VERSION ""

NS_ :

BS_:

BU_: BLE GEO IO MASTER MOTOR SENSOR

BO_ 010 BLE_COMM_CMD: 1 BLE
 SG_ BLE_COMM_CMD_enum : 0|8@1+ (1,0) [0|0] "" MASTER

BO_ 100 SYSTEM_CMD: 1 MASTER
 SG_ SYSTEM_CMD_enum : 0|8@1+ (1,0) [0|0] "" BLE,GEO,IO,MOTOR,SENSOR

BO_ 134 MASTER_HEARTBEAT: 4 MASTER
 SG_ MASTER_HEARTBEAT_rx_bytes : 0|16@1+ (1,0) [0|0] "" BLE
 SG_ MASTER_HEARTBEAT_tx_bytes : 16|16@1+ (1,0) [0|0] "" BLE

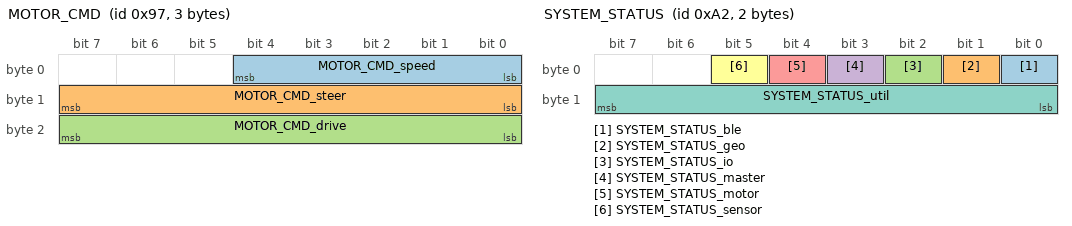
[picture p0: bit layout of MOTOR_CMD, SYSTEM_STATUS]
BO_ 151 MOTOR_CMD: 3 MASTER
 SG_ MOTOR_CMD_speed : 0|5@1+ (1,0) [10|20] "%" MOTOR,IO
 SG_ MOTOR_CMD_steer : 8|8@1+ (1,0) [0|0] "" MOTOR,IO
 SG_ MOTOR_CMD_drive : 16|8@1+ (1,0) [0|0] "" MOTOR,IO

BO_ 162 SYSTEM_STATUS: 2 MASTER
 SG_ SYSTEM_STATUS_ble : 0|1@1+ (1,0) [0|0] "" BLE,IO
 SG_ SYSTEM_STATUS_geo : 1|1@1+ (1,0) [0|0] "" BLE,IO
 SG_ SYSTEM_STATUS_io : 2|1@1+ (1,0) [0|0] "" BLE,IO
 SG_ SYSTEM_STATUS_master : 3|1@1+ (1,0) [0|0] "" BLE,IO
 SG_ SYSTEM_STATUS_motor : 4|1@1+ (1,0) [0|0] "" BLE,IO
 SG_ SYSTEM_STATUS_sensor : 5|1@1+ (1,0) [0|0] "" BLE,IO
 SG_ SYSTEM_STATUS_util : 8|8@1+ (1,0) [0|100] "%" BLE,IO

BO_ 211 SENSOR_ULTRASONIC: 7 SENSOR
 SG_ SENSOR_ULTRASONIC_mux M : 0|4@1+ (1,0) [0|0] "" MASTER
 SG_ SENSOR_ULTRASONIC_err_count : 4|12@1+ (1,0) [0|0] "" MASTER
 SG_ SENSOR_ULTRASONIC_left m0 : 16|8@1+ (1,0) [0|0] "" MASTER
 SG_ SENSOR_ULTRASONIC_middle m0 : 24|8@1+ (1,0) [0|0] "" MASTER
 SG_ SENSOR_ULTRASONIC_right m0 : 32|8@1+ (1,0) [0|0] "" MASTER
 SG_ SENSOR_ULTRASONIC_rear_right m0 : 40|8@1+ (1,0) [0|0] "" MASTER
 SG_ SENSOR_ULTRASONIC_rear_left m0 : 48|8@1+ (1,0) [0|0] "" MASTER
 SG_ SENSOR_ULTRASONIC_no_filt_left m1 : 16|8@1+ (1,0) [0|0] "" MASTER
 SG_ SENSOR_ULTRASONIC_no_filt_middle m1 : 24|8@1+ (1,0) [0|0] "" MASTER
 SG_ SENSOR_ULTRASONIC_no_filt_right m1 : 32|8@1+ (1,0) [0|0] "" MASTER
 SG_ SENSOR_ULTRASONIC_no_filt_rear_right m1 : 40|8@1+ (1,0) [0|0] "" MASTER
 SG_ SENSOR_ULTRASONIC_no_filt_rear_left m1 : 48|8@1+ (1,0) [0|0] "" MASTER

BO_ 212 SENSOR_SPEED: 1 SENSOR
 SG_ SENSOR_SPEED_data : 0|8@1+ (1,0) [0|0] "rpm" MASTER,IO,BLE

BO_ 213 SENSOR_BATT: 1 SENSOR
 SG_ SENSOR_BATT_stat : 0|7@1+ (1,0) [0|100] "%" MASTER,IO,BLE

BO_ 214 SENSOR_HEARTBEAT: 4 SENSOR
 SG_ SENSOR_HEARTBEAT_rx_bytes : 0|16@1+ (1,0) [0|0] "" MASTER
 SG_ SENSOR_HEARTBEAT_tx_bytes : 16|16@1+ (1,0) [0|0] "" MASTER

BO_ 311 BLE_CHCK_PT: 4 BLE
 SG_ BLE_CHCK_PT_lat : 0|16@1+ (1,0) [0|0] "" GEO
 SG_ BLE_CHCK_PT_long : 16|16@1+ (1,0) [0|0] "" GEO

BO_ 312 BLE_DEST_RCHD: 1 BLE
 SG_ BLE_DEST_RCHD_stat : 0|1@1+ (1,0) [0|1] "" MASTER,IO

BO_ 314 BLE_HEARTBEAT: 4 BLE
 SG_ BLE_HEARTBEAT_rx_bytes : 0|16@1+ (1,0) [0|0] "" MASTER
 SG_ BLE_HEARTBEAT_tx_bytes : 16|16@1+ (1,0) [0|0] "" MASTER

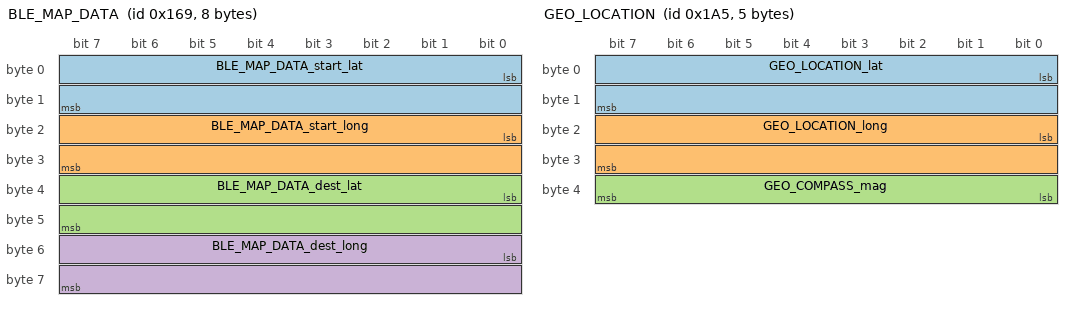
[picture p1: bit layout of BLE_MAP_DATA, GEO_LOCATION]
BO_ 361 BLE_MAP_DATA: 8 BLE
 SG_ BLE_MAP_DATA_start_lat : 0|16@1+ (1,0) [0|0] "" IO
 SG_ BLE_MAP_DATA_start_long : 16|16@1+ (1,0) [0|0] "" IO
 SG_ BLE_MAP_DATA_dest_lat : 32|16@1+ (1,0) [0|0] "" IO
 SG_ BLE_MAP_DATA_dest_long : 48|16@1+ (1,0) [0|0] "" IO

BO_ 411 GEO_DIRECTION: 1 GEO
 SG_ GEO_DIRECTION_data : 0|8@1+ (1,0) [0|0] "" MASTER

BO_ 412 GEO_ACCELEROMETER: 1 GEO
 SG_ GEO_ACCELEROMETER_tilt : 0|8@1+ (1,0) [0|0] "" MASTER

BO_ 414 GEO_HEARTBEAT: 4 GEO
 SG_ GEO_HEARTBEAT_rx_bytes : 0|16@1+ (1,0) [0|0] "" MASTER
 SG_ GEO_HEARTBEAT_tx_bytes : 16|16@1+ (1,0) [0|0] "" MASTER

BO_ 421 GEO_LOCATION: 5 GEO
 SG_ GEO_LOCATION_lat : 0|16@1+ (1,0) [0|0] "" BLE,IO
 SG_ GEO_LOCATION_long : 16|16@1+ (1,0) [0|0] "" BLE,IO
 SG_ GEO_COMPASS_mag : 32|8@1+ (1,0) [0|0] "" BLE,IO

BO_ 514 MOTOR_HEARTBEAT: 4 MOTOR
 SG_ MOTOR_HEARTBEAT_rx_bytes : 0|16@1+ (1,0) [0|0] "" MASTER
 SG_ MOTOR_HEARTBEAT_tx_bytes : 16|16@1+ (1,0) [0|0] "" MASTER

BO_ 614 IO_HEARTBEAT: 4 IO
 SG_ IO_HEARTBEAT_rx_bytes : 0|16@1+ (1,0) [0|0] "" MASTER
 SG_ IO_HEARTBEAT_tx_bytes : 16|16@1+ (1,0) [0|0] "" MASTER

CM_ BU_ BLE "The communication bridge module of the car";
CM_ BU_ GEO "The geocontroller module of the car";
CM_ BU_ IO "The input output controller of the car";
CM_ BU_ MASTER "The master controller of the car";
CM_ BU_ MOTOR "The motor controller of the car";
CM_ BU_ SENSOR "The sensor controller of the car";
CM_ BO_ 010 "The wake-up message for the master controller";
CM_ BO_ 100 "The system commands for all the modules";

BA_DEF_ "BusType" STRING ;
BA_DEF_ BO_ "GenMsgCycleTime" INT 0 0;
BA_DEF_ SG_ "FieldType" STRING ;

BA_DEF_DEF_ "BusType" "CAN";
BA_DEF_DEF_ "FieldType" "";
BA_DEF_DEF_ "GenMsgCycleTime" 0;

BA_ "GenMsgCycleTime" BO_ 134 1000;
BA_ "GenMsgCycleTime" BO_ 214 1000;
BA_ "GenMsgCycleTime" BO_ 314 1000;
BA_ "GenMsgCycleTime" BO_ 414 1000;
BA_ "GenMsgCycleTime" BO_ 514 1000;
BA_ "GenMsgCycleTime" BO_ 614 1000;
BA_ "FieldType" SG_ 011 COMM_CMD_enum "COMM_CMD";
BA_ "FieldType" SG_ 100 SYSTEM_CMD_enum "SYSTEM_CMD";
BA_ "FieldType" SG_ 151 MOTOR_CMD_steer "MOTOR_STEER";
BA_ "FieldType" SG_ 151 MOTOR_CMD_drive "MOTOR_DRIVE";

VAL_ 011 COMM_CMD_enum 0 "COMM_STOP" 1 "COMM_START" 2 "COMM_RESET" ;
VAL_ 100 SYSTEM_CMD_enum 0 "SYSTEM_STOP" 1 "SYSTEM_START" 2 "SYSTEM_RESET" ;
VAL_ 151 MOTOR_CMD_steer 0 "STEER_LEFT" 1 "STEER_HALF_LEFT" 2 "STEER_RIGHT" 3 "STEER_HALF_RIGHT" 4 "STEER_FORWARD" 5 "STEER_REVERSE";
VAL_ 151 MOTOR_CMD_drive 0 "STOP" 1 "START" 2 "BRAKE" 3 "RESUME";
